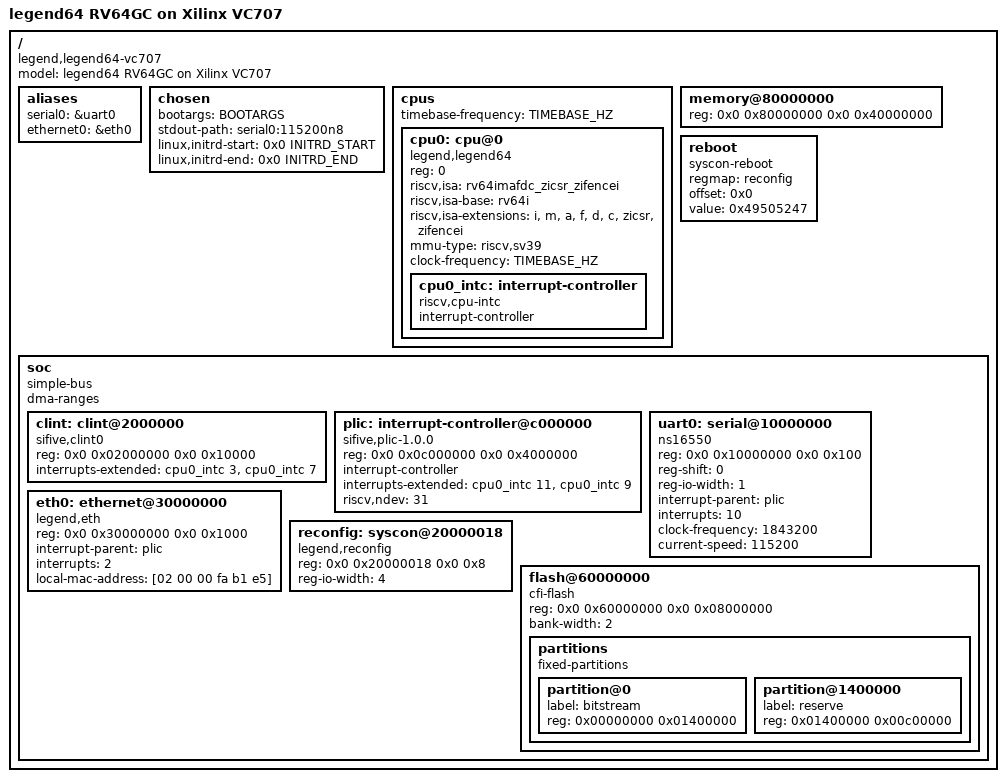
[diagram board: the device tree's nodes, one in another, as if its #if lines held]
// SPDX-License-Identifier: (GPL-2.0-only OR MIT)
/*
 * legend64 on the Xilinx VC707 - one RV64GC hart, Sv39, 1 GiB RAM.
 * The memory map mirrors QEMU's "virt" machine for CLINT, PLIC and UART.
 *
 * This file goes through the C preprocessor (see build-dtb.sh):
 *   TIMEBASE_HZ   mtime tick rate = CPU clock (the one value to change if the
 *                 clock changes), default 50 MHz
 *   BOOTARGS      kernel command line, default = NFS root
 *   INITRD_START / INITRD_END   when defined, describe a preloaded initramfs
 */
#ifndef TIMEBASE_HZ
#define TIMEBASE_HZ 50000000
#endif
#ifndef BOOTARGS
#define BOOTARGS "console=ttyS0,115200 earlycon root=/dev/nfs nfsroot=192.168.1.176:/srv/nfs/fable64,vers=3,tcp,rsize=32768,wsize=32768 rw ip=192.168.1.51::192.168.1.1:255.255.255.0:legend64:eth0:off"
#endif

/dts-v1/;

/ {
	#address-cells = <2>;
	#size-cells = <2>;
	compatible = "legend,legend64-vc707", "legend,legend64";
	model = "legend64 RV64GC on Xilinx VC707";

	aliases {
		serial0 = &uart0;
		ethernet0 = &eth0;
	};

	chosen {
		bootargs = BOOTARGS;
		stdout-path = "serial0:115200n8";
#ifdef INITRD_START
		linux,initrd-start = <0x0 INITRD_START>;
		linux,initrd-end = <0x0 INITRD_END>;
#endif
	};

	cpus {
		#address-cells = <1>;
		#size-cells = <0>;
		timebase-frequency = <TIMEBASE_HZ>;

		cpu0: cpu@0 {
			device_type = "cpu";
			compatible = "legend,legend64", "riscv";
			reg = <0>;
			status = "okay";
			/* No Zicntr (no time CSR), Zihpm, Sstc, Zb*, V, Zicbo*, PMP. */
			riscv,isa = "rv64imafdc_zicsr_zifencei";
			riscv,isa-base = "rv64i";
			riscv,isa-extensions = "i", "m", "a", "f", "d", "c",
					       "zicsr", "zifencei";
			mmu-type = "riscv,sv39";
			clock-frequency = <TIMEBASE_HZ>;

			cpu0_intc: interrupt-controller {
				compatible = "riscv,cpu-intc";
				#interrupt-cells = <1>;
				interrupt-controller;
			};
		};
	};

	memory@80000000 {
		device_type = "memory";
		reg = <0x0 0x80000000 0x0 0x40000000>;	/* 1 GiB */
	};

	/* a reboot is a reload of the FPGA from its flash: everything starts cold */
	reboot {
		compatible = "syscon-reboot";
		regmap = <&reconfig>;
		offset = <0x0>;
		value = <0x49505247>;
	};

	soc {
		compatible = "simple-bus";
		#address-cells = <2>;
		#size-cells = <2>;
		ranges;
		/* Bus-mastering devices see RAM at its CPU physical address
		 * (identity, no IOMMU).  RISC-V devices are DMA-coherent by
		 * default, which is what the hardware is, so no further
		 * property is needed. */
		dma-ranges;

		clint: clint@2000000 {
			compatible = "sifive,clint0", "riscv,clint0";
			reg = <0x0 0x02000000 0x0 0x10000>;
			/* M-mode software (3) and timer (7) interrupts */
			interrupts-extended = <&cpu0_intc 3>, <&cpu0_intc 7>;
		};

		plic: interrupt-controller@c000000 {
			compatible = "sifive,plic-1.0.0", "riscv,plic0";
			reg = <0x0 0x0c000000 0x0 0x4000000>;
			#address-cells = <0>;
			#interrupt-cells = <1>;
			interrupt-controller;
			/* context 0 = hart0 M-external, context 1 = hart0 S-external */
			interrupts-extended = <&cpu0_intc 11>, <&cpu0_intc 9>;
			riscv,ndev = <31>;
		};

		uart0: serial@10000000 {
			/* no transmit FIFO: "ns16550a" would make the 8250 driver write 16 bytes per interrupt */
			compatible = "ns16550";
			reg = <0x0 0x10000000 0x0 0x100>;
			reg-shift = <0>;
			reg-io-width = <1>;
			interrupt-parent = <&plic>;
			interrupts = <10>;
			/* The hardware ignores the divisor latch: always 115200 8N1. */
			clock-frequency = <1843200>;
			current-speed = <115200>;
		};

		/*
		 * Native descriptor-ring MAC, DMA straight to/from system RAM.
		 * PLACEHOLDER: the register interface and its Linux driver
		 * (CONFIG_LEGEND_ETH, kernel/patches/legend-eth.patch) are pending;
		 * until then nothing binds to this node.
		 */
		eth0: ethernet@30000000 {
			compatible = "legend,eth";
			reg = <0x0 0x30000000 0x0 0x1000>;
			interrupt-parent = <&plic>;
			interrupts = <2>;
			local-mac-address = [02 00 00 fa b1 e5];
		};

		/*
		 * The register that reloads the FPGA from its flash, as a syscon of
		 * its own so that the reboot node's offset is 0: OpenSBI, which
		 * takes the reboot call, accepts only offsets that are multiples of
		 * 32 in a syscon (v1.8.1 sets the stride to the width in bits).
		 */
		reconfig: syscon@20000018 {
			compatible = "legend,reconfig", "syscon";
			reg = <0x0 0x20000018 0x0 0x8>;
			reg-io-width = <4>;
		};

		/*
		 * The FPGA's configuration flash (128 MiB, 16 bits wide) through an
		 * asynchronous bus bridge. Switch SW11 drives its top two address
		 * lines, so only the 32 MiB image the board boots from can be reached:
		 * it appears four times over in the device's 128 MiB, and the
		 * partitions below cover the first. The whole device is mapped
		 * because the driver writes a reset command to each of the device's
		 * eight internal partitions on reboot, wherever the mapping ends.
		 */
		flash@60000000 {
			compatible = "cfi-flash";
			reg = <0x0 0x60000000 0x0 0x08000000>;
			bank-width = <2>;

			partitions {
				compatible = "fixed-partitions";
				#address-cells = <1>;
				#size-cells = <1>;

				partition@0 {
					label = "bitstream";
					reg = <0x00000000 0x01400000>;
				};
				partition@1400000 {
					/* JFFS2: a kernel and a small root for when the network is away */
					label = "reserve";
					reg = <0x01400000 0x00c00000>;
				};
			};
		};
	};
};
